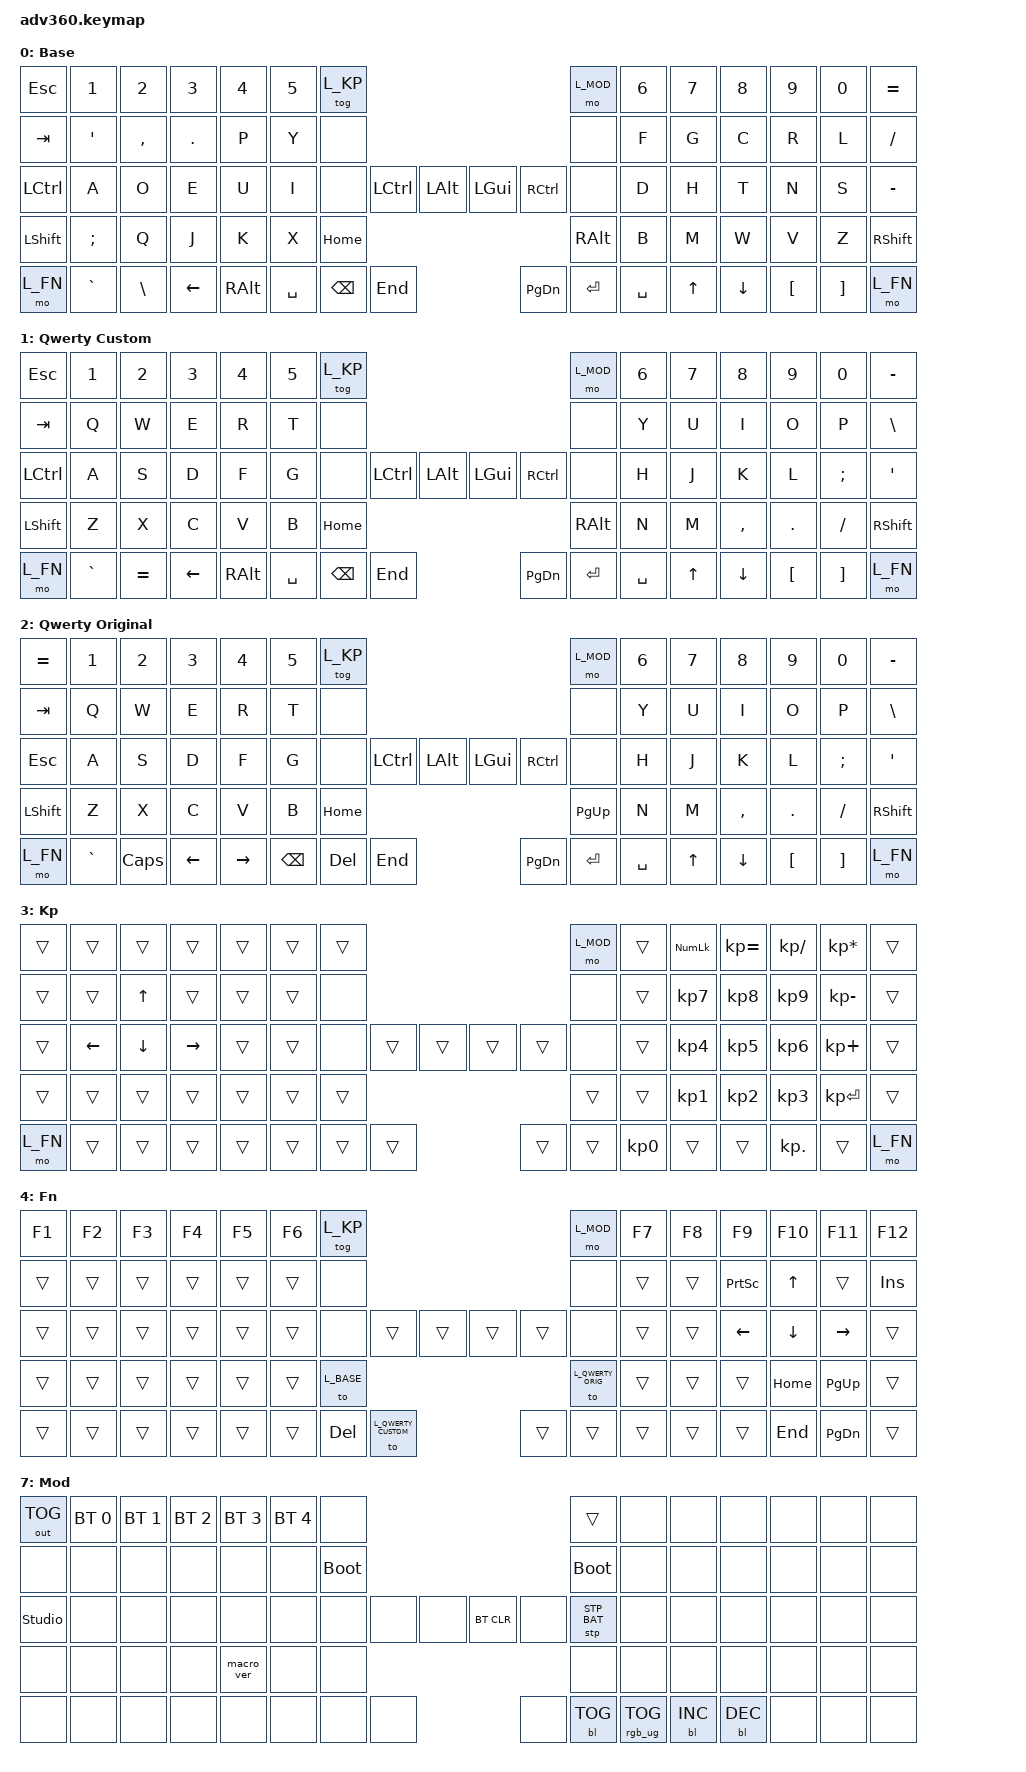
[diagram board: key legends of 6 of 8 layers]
#include <behaviors.dtsi>
#include <dt-bindings/zmk/keys.h>
#include <dt-bindings/zmk/bt.h>
#include <dt-bindings/zmk/rgb.h>
#include <dt-bindings/zmk/stp.h>
#include <dt-bindings/zmk/backlight.h>
#include <dt-bindings/zmk/outputs.h>
#include <dt-bindings/zmk/pointing.h>

// Layer numbers
#define L_BASE 0
#define L_QWERTY_CUSTOM 1
#define L_QWERTY_ORIG 2
#define L_KP 3
#define L_FN 4
#define L_EXTRA1 5
#define L_EXTRA2 6
#define L_MOD 7

/ {
    behaviors {
      #include "macros.dtsi"
      #include "version.dtsi"

      hm: homerow_mods {
          compatible = "zmk,behavior-hold-tap";
          label = "HOMEROW_MODS";
          #binding-cells = <2>;
          tapping-term-ms = <200>;
          quick_tap_ms = <175>;
          flavor = "tap-preferred";
          bindings = <&kp>, <&kp>;
      };
    };

  keymap {
    compatible = "zmk,keymap";

    // layer 0: Dvorak
    // 現用しているキーマップとの違い: ESC ↔ \ (バックスラッシュ)
    default_layer {
      display-name = "Base";
      bindings = <
        &kp ESC   &kp N1    &kp N2    &kp N3   &kp N4     &kp N5 &tog L_KP                                                         &mo L_MOD &kp N6 &kp N7 &kp N8   &kp N9   &kp N0   &kp EQUAL
        &kp TAB   &kp SQT   &kp COMMA &kp DOT  &kp P      &kp Y  &none                                                             &none     &kp F  &kp G  &kp C    &kp R    &kp L    &kp FSLH
        &kp LCTRL &kp A     &kp O     &kp E    &kp U      &kp I  &none            &kp LCTRL &kp LALT &kp LGUI  &kp RCTRL           &none     &kp D  &kp H  &kp T    &kp N    &kp S    &kp MINUS
        &kp LSHFT &kp SEMI  &kp Q     &kp J    &kp K      &kp X                             &kp HOME &kp RALT                               &kp B  &kp M  &kp W    &kp V    &kp Z    &kp RSHFT
        &mo L_FN  &kp GRAVE &kp BSLH  &kp LEFT &kp RALT                 &kp SPACE &kp BSPC  &kp END  &kp PG_DN &kp ENTER &kp SPACE                  &kp UP &kp DOWN &kp LBKT &kp RBKT &mo L_FN
      >;
    };

    // layer 1
    qwerty_custom_layer {
      display-name = "Qwerty Custom";
      bindings = <
        &kp ESC   &kp N1    &kp N2    &kp N3   &kp N4     &kp N5 &tog L_KP                                                         &mo L_MOD &kp N6 &kp N7 &kp N8    &kp N9   &kp N0   &kp MINUS
        &kp TAB   &kp Q     &kp W     &kp E    &kp R      &kp T  &none                                                             &none     &kp Y  &kp U  &kp I     &kp O    &kp P    &kp BSLH
        &kp LCTRL &kp A     &kp S     &kp D    &kp F      &kp G  &none            &kp LCTRL &kp LALT &kp LGUI  &kp RCTRL           &none     &kp H  &kp J  &kp K     &kp L    &kp SEMI &kp SQT
        &kp LSHFT &kp Z     &kp X     &kp C    &kp V      &kp B                             &kp HOME &kp RALT                               &kp N  &kp M  &kp COMMA &kp DOT  &kp FSLH &kp RSHFT
        &mo L_FN  &kp GRAVE &kp EQUAL &kp LEFT &kp RALT                 &kp SPACE &kp BSPC  &kp END  &kp PG_DN &kp ENTER &kp SPACE                  &kp UP &kp DOWN  &kp LBKT &kp RBKT &mo L_FN
      >;
    };

    // layer 2: キーの刻印通りのデフォルトの配列を保存するレイヤー。このレイヤーは変更しないでください。
    qwerty_orig_layer {
      display-name = "Qwerty Original";
      bindings = <
        &kp EQUAL &kp N1    &kp N2   &kp N3   &kp N4     &kp N5 &tog L_KP                                                        &mo L_MOD &kp N6 &kp N7 &kp N8    &kp N9   &kp N0   &kp MINUS
        &kp TAB   &kp Q     &kp W    &kp E    &kp R      &kp T  &none                                                            &none     &kp Y  &kp U  &kp I     &kp O    &kp P    &kp BSLH
        &kp ESC   &kp A     &kp S    &kp D    &kp F      &kp G  &none           &kp LCTRL &kp LALT &kp LGUI  &kp RCTRL           &none     &kp H  &kp J  &kp K     &kp L    &kp SEMI &kp SQT
        &kp LSHFT &kp Z     &kp X    &kp C    &kp V      &kp B                            &kp HOME &kp PG_UP                               &kp N  &kp M  &kp COMMA &kp DOT  &kp FSLH &kp RSHFT
        &mo L_FN  &kp GRAVE &kp CAPS &kp LEFT &kp RIGHT                &kp BSPC &kp DEL   &kp END  &kp PG_DN &kp ENTER &kp SPACE                  &kp UP &kp DOWN  &kp LBKT &kp RBKT &mo L_FN
      >;
    };

    // layer 3
    keypad {
      display-name = "Kp";
      bindings = <
        &trans    &trans   &trans   &trans    &trans &trans &trans                                                           &mo L_MOD &trans &kp KP_NUM &kp KP_EQUAL &kp KP_DIVIDE &kp KP_MULTIPLY &trans
        &trans    &trans   &kp UP   &trans    &trans &trans &none                                                            &none     &trans &kp KP_N7  &kp KP_N8    &kp KP_N9     &kp KP_MINUS    &trans
        &trans    &kp LEFT &kp DOWN &kp RIGHT &trans &trans &none           &trans    &trans   &trans    &trans              &none     &trans &kp KP_N4  &kp KP_N5    &kp KP_N6     &kp KP_PLUS     &trans
        &trans    &trans   &trans   &trans    &trans &trans                           &trans   &trans                                  &trans &kp KP_N1  &kp KP_N2    &kp KP_N3     &kp KP_ENTER    &trans
        &mo L_FN  &trans   &trans   &trans    &trans               &trans   &trans    &trans   &trans    &trans    &kp KP_N0                  &trans     &trans       &kp KP_DOT    &trans          &mo L_FN
      >;
    };

    // layer 4
    fn {
      display-name = "Fn";
      bindings = <
        &kp F1 &kp F2 &kp F3 &kp F4 &kp F5 &kp F6 &tog L_KP                                                                     &mo L_MOD &kp F7 &kp F8 &kp F9    &kp F10  &kp F11     &kp F12
        &trans &trans &trans &trans &trans &trans &none                                                                         &none     &trans &trans &kp PSCRN &kp UP   &trans      &kp INS
        &trans &trans &trans &trans &trans &trans &none                           &trans &trans &trans            &trans        &none     &trans &trans &kp LEFT  &kp DOWN &kp RIGHT   &trans
        &trans &trans &trans &trans &trans &trans                                    &to L_BASE &to L_QWERTY_ORIG                         &trans &trans &trans    &kp HOME &kp PG_UP   &trans
        &trans &trans &trans &trans &trans                  &trans &kp DEL  &to L_QWERTY_CUSTOM &trans            &trans &trans                  &trans &trans    &kp END  &kp PG_DN &trans
      >;
    };

    // layer 5
    extra1 { 
      display-name = "Extra1";
      bindings = <
        &trans &trans &trans &trans &trans &trans &trans                                                                &trans &trans &trans &trans &trans &trans &trans
        &trans &trans &trans &trans &trans &trans &trans                                                                &trans &trans &trans &trans &trans &trans &trans
        &trans &trans &trans &trans &trans &trans &trans            &trans &trans &trans &trans            &trans       &trans &trans &trans &trans &trans &trans &trans
        &trans &trans &trans &trans &trans &trans                           &trans &trans                                 &trans &trans &trans &trans &trans &trans
        &trans &trans &trans &trans &trans                  &trans &trans &trans &trans            &trans &trans              &trans &trans &trans &trans &trans
      >;
    };

    // layer 6
    extra2 { 
      display-name = "Extra2";
      bindings = <
        &trans &trans &trans &trans &trans &trans &trans                                                                &trans &trans &trans &trans &trans &trans &trans
        &trans &trans &trans &trans &trans &trans &trans                                                                &trans &trans &trans &trans &trans &trans &trans
        &trans &trans &trans &trans &trans &trans &trans            &trans &trans &trans &trans            &trans       &trans &trans &trans &trans &trans &trans &trans
        &trans &trans &trans &trans &trans &trans                           &trans &trans                                 &trans &trans &trans &trans &trans &trans
        &trans &trans &trans &trans &trans                  &trans &trans &trans &trans            &trans &trans              &trans &trans &trans &trans &trans
      >;
    };

    // layer 7
    mod {
      display-name = "Mod";
      bindings = <
        &out OUT_TOG   &bt BT_SEL 0 &bt BT_SEL 1 &bt BT_SEL 2 &bt BT_SEL 3 &bt BT_SEL 4 &none                                                               &trans       &none        &none        &none        &none &none &none
        &none          &none        &none        &none        &none        &none        &bootloader                                                         &bootloader  &none        &none        &none        &none &none &none
        &studio_unlock &none        &none        &none        &none        &none        &none             &none &none &bt BT_CLR &none                      &stp STP_BAT &none        &none        &none        &none &none &none
        &none          &none        &none        &none        &macro_ver   &none                                &none &none                                              &none        &none        &none        &none &none &none
        &none          &none        &none        &none        &none                                 &none &none &none &none      &bl BL_TOG &rgb_ug RGB_TOG                           &bl BL_INC   &bl BL_DEC   &none &none &none
      >;
    };
  };
};
